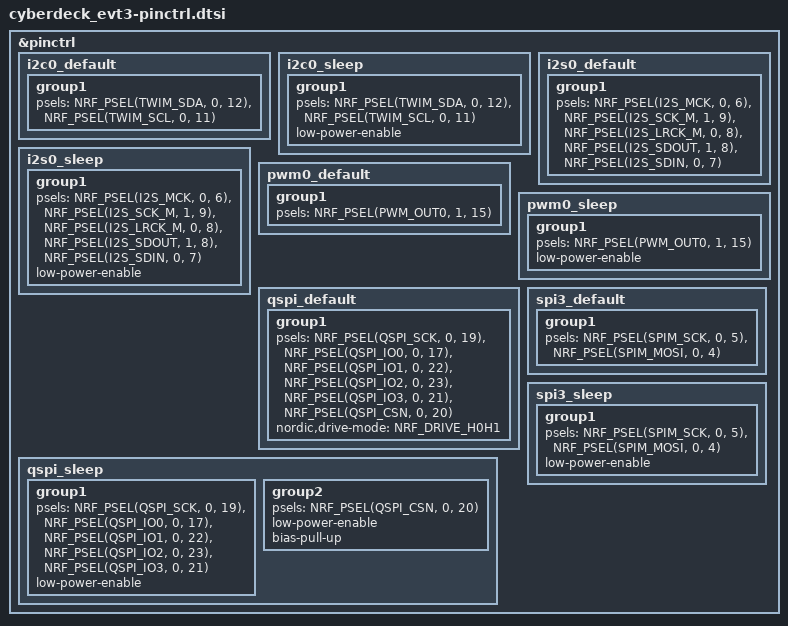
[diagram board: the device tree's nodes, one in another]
&pinctrl {
	i2c0_default: i2c0_default {
		group1 {
			psels = <NRF_PSEL(TWIM_SDA, 0, 12)>,
				<NRF_PSEL(TWIM_SCL, 0, 11)>;
		};
	};

	i2c0_sleep: i2c0_sleep {
		group1 {
			psels = <NRF_PSEL(TWIM_SDA, 0, 12)>,
				<NRF_PSEL(TWIM_SCL, 0, 11)>;
			low-power-enable;
		};
	};

	i2s0_default: i2s0_default {
		group1 {
			psels = <NRF_PSEL(I2S_MCK, 0, 6)>,
				<NRF_PSEL(I2S_SCK_M, 1, 9)>,
				<NRF_PSEL(I2S_LRCK_M, 0, 8)>,
				<NRF_PSEL(I2S_SDOUT, 1, 8)>,
				<NRF_PSEL(I2S_SDIN, 0, 7)>;
		};
	};

	i2s0_sleep: i2s0_sleep {
		group1 {
			psels = <NRF_PSEL(I2S_MCK, 0, 6)>,
				<NRF_PSEL(I2S_SCK_M, 1, 9)>,
				<NRF_PSEL(I2S_LRCK_M, 0, 8)>,
				<NRF_PSEL(I2S_SDOUT, 1, 8)>,
				<NRF_PSEL(I2S_SDIN, 0, 7)>;
			low-power-enable;
		};
	};

	pwm0_default: pwm0_default {
		group1 {
			psels = <NRF_PSEL(PWM_OUT0, 1, 15)>;
		};
	};

	pwm0_sleep: pwm0_sleep {
		group1 {
			psels = <NRF_PSEL(PWM_OUT0, 1, 15)>;
			low-power-enable;
		};
	};

	qspi_default: qspi_default {
		group1 {
			psels = <NRF_PSEL(QSPI_SCK, 0, 19)>,
				<NRF_PSEL(QSPI_IO0, 0, 17)>,
				<NRF_PSEL(QSPI_IO1, 0, 22)>,
				<NRF_PSEL(QSPI_IO2, 0, 23)>,
				<NRF_PSEL(QSPI_IO3, 0, 21)>,
				<NRF_PSEL(QSPI_CSN, 0, 20)>;
			nordic,drive-mode = <NRF_DRIVE_H0H1>;
		};
	};

	qspi_sleep: qspi_sleep {
		group1 {
			psels = <NRF_PSEL(QSPI_SCK, 0, 19)>,
				<NRF_PSEL(QSPI_IO0, 0, 17)>,
				<NRF_PSEL(QSPI_IO1, 0, 22)>,
				<NRF_PSEL(QSPI_IO2, 0, 23)>,
				<NRF_PSEL(QSPI_IO3, 0, 21)>;
			low-power-enable;
		};
		group2 {
			psels = <NRF_PSEL(QSPI_CSN, 0, 20)>;
			low-power-enable;
			bias-pull-up;
		};
	};

	spi3_default: spi3_default {
		group1 {
			psels = <NRF_PSEL(SPIM_SCK, 0, 5)>,
				<NRF_PSEL(SPIM_MOSI, 0, 4)>;
		};
	};

	spi3_sleep: spi3_sleep {
		group1 {
			psels = <NRF_PSEL(SPIM_SCK, 0, 5)>,
				<NRF_PSEL(SPIM_MOSI, 0, 4)>;
			low-power-enable;
		};
	};
};
